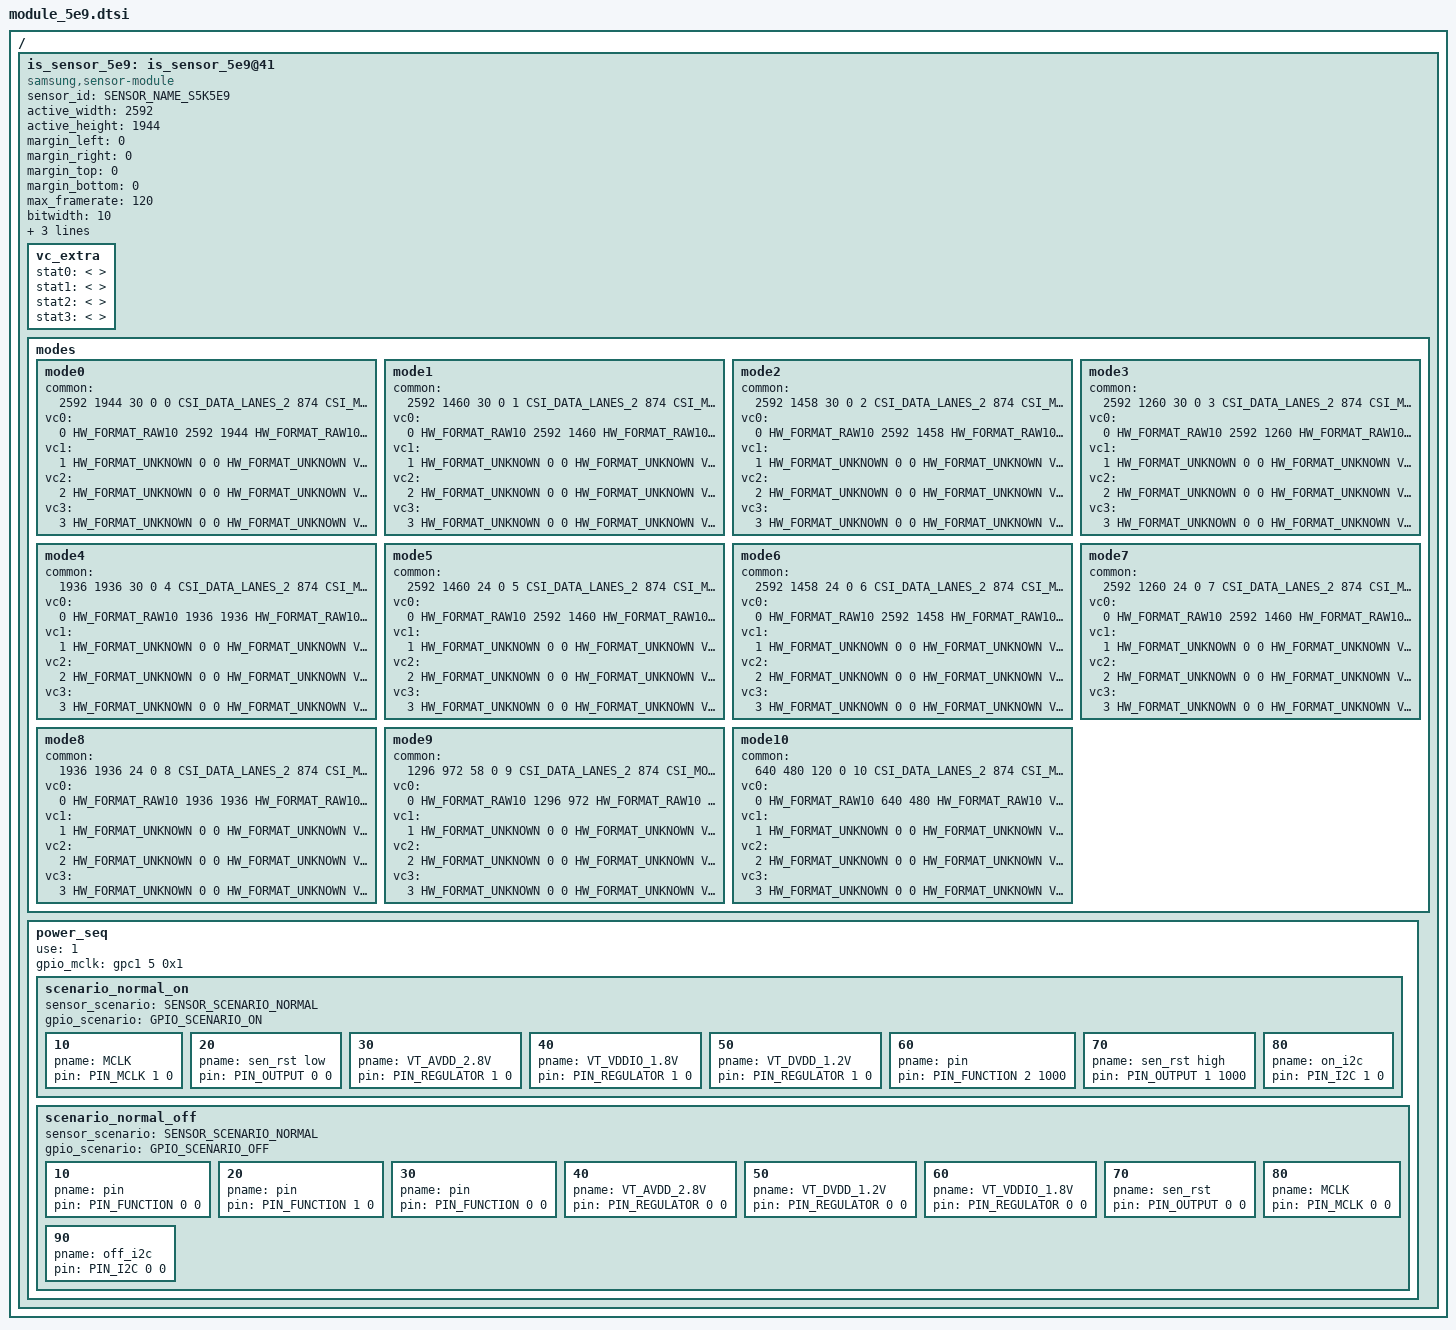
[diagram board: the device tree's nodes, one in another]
/*
 * SAMSUNG EXYNOSxxxx board camera device tree source
 *
 * Copyright (c) 2019 Samsung Electronics Co., Ltd.
 *		http://www.samsung.com
 *
 * This program is free software; you can redistribute it and/or modify
 * it under the terms of the GNU General Public License version 2 as
 * published by the Free Software Foundation.
 */

#include <dt-bindings/camera/exynos_is_dt.h>

/ {
	fragment@camera {
		target-path = "/";
		__overlay__ {
			is_sensor_5e9: is_sensor_5e9@41 {
				compatible = "samsung,sensor-module";

				/* common */
				sensor_id = <SENSOR_NAME_S5K5E9>;
				active_width = <2592>;
				active_height = <1944>;
				margin_left = <0>;
				margin_right = <0>;
				margin_top = <0>;
				margin_bottom = <0>;
				max_framerate = <120>;
				bitwidth = <10>;
				sensor_maker = "SLSI";
				sensor_name = "S5K5E9";
				setfile_name = "setfile_5e9.bin";

				status = "okay";

				vc_extra {
					/* ex) statX = <stat_type, sensor_mode, max_width, max_height, max_element> */
					stat0 = </* not avaliable */>;	/* VC_BUF_DATA_TYPE_SENSOR_STAT1 */
					stat1 = </* not avaliable */>;	/* VC_BUF_DATA_TYPE_GENERAL_STAT1 */
					stat2 = </* not avaliable */>;	/* VC_BUF_DATA_TYPE_SENSOR_STAT2 */
					stat3 = </* not avaliable */>;	/* VC_BUF_DATA_TYPE_GENERAL_STAT2 */
				};

				/* sensor modes */
				modes {
						/* common = <width, height, fps, settle, mode, lane, speed, interleave, lrte, pd_mode> */
						/* vcX = <map, hwformat, width, height, hwformat, type, width, height> */
					mode0 {
						common = <2592 1944 30 0 0 CSI_DATA_LANES_2 874 CSI_MODE_VC_ONLY LRTE_DISABLE PD_NONE EX_NONE>;
						vc0 = </* in */ 0 HW_FORMAT_RAW10 2592 1944	/* out */ HW_FORMAT_RAW10 VC_NOTHING 2592 1944>;
						vc1 = </* in */ 1 HW_FORMAT_UNKNOWN 0 0		/* out */ HW_FORMAT_UNKNOWN VC_NOTHING 0 0>;
						vc2 = </* in */ 2 HW_FORMAT_UNKNOWN 0 0		/* out */ HW_FORMAT_UNKNOWN VC_NOTHING 0 0>;
						vc3 = </* in */ 3 HW_FORMAT_UNKNOWN 0 0		/* out */ HW_FORMAT_UNKNOWN VC_NOTHING 0 0>;
					};
					mode1 {
						common = <2592 1460 30 0 1 CSI_DATA_LANES_2 874 CSI_MODE_VC_ONLY LRTE_DISABLE PD_NONE EX_NONE>;
						vc0 = <0 HW_FORMAT_RAW10 2592 1460	/* out */ HW_FORMAT_RAW10 VC_NOTHING 0 0>;
						vc1 = <1 HW_FORMAT_UNKNOWN 0 0		/* out */ HW_FORMAT_UNKNOWN VC_NOTHING 0 0>;
						vc2 = <2 HW_FORMAT_UNKNOWN 0 0		/* out */ HW_FORMAT_UNKNOWN VC_NOTHING 0 0>;
						vc3 = <3 HW_FORMAT_UNKNOWN 0 0		/* out */ HW_FORMAT_UNKNOWN VC_NOTHING 0 0>;
					};
					mode2 {
						common = <2592 1458 30 0 2 CSI_DATA_LANES_2 874 CSI_MODE_VC_ONLY LRTE_DISABLE PD_NONE EX_NONE>;
						vc0 = <0 HW_FORMAT_RAW10 2592 1458	/* out */ HW_FORMAT_RAW10 VC_NOTHING 0 0>;
						vc1 = <1 HW_FORMAT_UNKNOWN 0 0		/* out */ HW_FORMAT_UNKNOWN VC_NOTHING 0 0>;
						vc2 = <2 HW_FORMAT_UNKNOWN 0 0		/* out */ HW_FORMAT_UNKNOWN VC_NOTHING 0 0>;
						vc3 = <3 HW_FORMAT_UNKNOWN 0 0		/* out */ HW_FORMAT_UNKNOWN VC_NOTHING 0 0>;
					};
					mode3 {
						common = <2592 1260 30 0 3 CSI_DATA_LANES_2 874 CSI_MODE_VC_ONLY LRTE_DISABLE PD_NONE EX_NONE>;
						vc0 = <0 HW_FORMAT_RAW10 2592 1260	/* out */ HW_FORMAT_RAW10 VC_NOTHING 0 0>;
						vc1 = <1 HW_FORMAT_UNKNOWN 0 0		/* out */ HW_FORMAT_UNKNOWN VC_NOTHING 0 0>;
						vc2 = <2 HW_FORMAT_UNKNOWN 0 0		/* out */ HW_FORMAT_UNKNOWN VC_NOTHING 0 0>;
						vc3 = <3 HW_FORMAT_UNKNOWN 0 0		/* out */ HW_FORMAT_UNKNOWN VC_NOTHING 0 0>;
					};
					mode4 {
						common = <1936 1936 30 0 4 CSI_DATA_LANES_2 874 CSI_MODE_VC_ONLY LRTE_DISABLE PD_NONE EX_NONE>;
						vc0 = <0 HW_FORMAT_RAW10 1936 1936	/* out */ HW_FORMAT_RAW10 VC_NOTHING 0 0>;
						vc1 = <1 HW_FORMAT_UNKNOWN 0 0		/* out */ HW_FORMAT_UNKNOWN VC_NOTHING 0 0>;
						vc2 = <2 HW_FORMAT_UNKNOWN 0 0		/* out */ HW_FORMAT_UNKNOWN VC_NOTHING 0 0>;
						vc3 = <3 HW_FORMAT_UNKNOWN 0 0		/* out */ HW_FORMAT_UNKNOWN VC_NOTHING 0 0>;
					};
					mode5 {
						common = <2592 1460 24 0 5 CSI_DATA_LANES_2 874 CSI_MODE_VC_ONLY LRTE_DISABLE PD_NONE EX_NONE>;
						vc0 = <0 HW_FORMAT_RAW10 2592 1460	/* out */ HW_FORMAT_RAW10 VC_NOTHING 0 0>;
						vc1 = <1 HW_FORMAT_UNKNOWN 0 0		/* out */ HW_FORMAT_UNKNOWN VC_NOTHING 0 0>;
						vc2 = <2 HW_FORMAT_UNKNOWN 0 0		/* out */ HW_FORMAT_UNKNOWN VC_NOTHING 0 0>;
						vc3 = <3 HW_FORMAT_UNKNOWN 0 0		/* out */ HW_FORMAT_UNKNOWN VC_NOTHING 0 0>;
					};
					mode6 {
						common = <2592 1458 24 0 6 CSI_DATA_LANES_2 874 CSI_MODE_VC_ONLY LRTE_DISABLE PD_NONE EX_NONE>;
						vc0 = <0 HW_FORMAT_RAW10 2592 1458	/* out */ HW_FORMAT_RAW10 VC_NOTHING 0 0>;
						vc1 = <1 HW_FORMAT_UNKNOWN 0 0		/* out */ HW_FORMAT_UNKNOWN VC_NOTHING 0 0>;
						vc2 = <2 HW_FORMAT_UNKNOWN 0 0		/* out */ HW_FORMAT_UNKNOWN VC_NOTHING 0 0>;
						vc3 = <3 HW_FORMAT_UNKNOWN 0 0		/* out */ HW_FORMAT_UNKNOWN VC_NOTHING 0 0>;
					};
					mode7 {
						common = <2592 1260 24 0 7 CSI_DATA_LANES_2 874 CSI_MODE_VC_ONLY LRTE_DISABLE PD_NONE EX_NONE>;
						vc0 = <0 HW_FORMAT_RAW10 2592 1460	/* out */ HW_FORMAT_RAW10 VC_NOTHING 0 0>;
						vc1 = <1 HW_FORMAT_UNKNOWN 0 0		/* out */ HW_FORMAT_UNKNOWN VC_NOTHING 0 0>;
						vc2 = <2 HW_FORMAT_UNKNOWN 0 0		/* out */ HW_FORMAT_UNKNOWN VC_NOTHING 0 0>;
						vc3 = <3 HW_FORMAT_UNKNOWN 0 0		/* out */ HW_FORMAT_UNKNOWN VC_NOTHING 0 0>;
					};
					mode8 {
						common = <1936 1936 24 0 8 CSI_DATA_LANES_2 874 CSI_MODE_VC_ONLY LRTE_DISABLE PD_NONE EX_NONE>;
						vc0 = <0 HW_FORMAT_RAW10 1936 1936	/* out */ HW_FORMAT_RAW10 VC_NOTHING 0 0>;
						vc1 = <1 HW_FORMAT_UNKNOWN 0 0		/* out */ HW_FORMAT_UNKNOWN VC_NOTHING 0 0>;
						vc2 = <2 HW_FORMAT_UNKNOWN 0 0		/* out */ HW_FORMAT_UNKNOWN VC_NOTHING 0 0>;
						vc3 = <3 HW_FORMAT_UNKNOWN 0 0		/* out */ HW_FORMAT_UNKNOWN VC_NOTHING 0 0>;
					};
					mode9 {
						common = <1296 972 58 0 9 CSI_DATA_LANES_2 874 CSI_MODE_VC_ONLY LRTE_DISABLE PD_NONE EX_NONE>;
						vc0 = <0 HW_FORMAT_RAW10 1296 972	/* out */ HW_FORMAT_RAW10 VC_NOTHING 0 0>;
						vc1 = <1 HW_FORMAT_UNKNOWN 0 0		/* out */ HW_FORMAT_UNKNOWN VC_NOTHING 0 0>;
						vc2 = <2 HW_FORMAT_UNKNOWN 0 0		/* out */ HW_FORMAT_UNKNOWN VC_NOTHING 0 0>;
						vc3 = <3 HW_FORMAT_UNKNOWN 0 0		/* out */ HW_FORMAT_UNKNOWN VC_NOTHING 0 0>;
					};
					mode10 {
						common = <640 480 120 0 10 CSI_DATA_LANES_2 874 CSI_MODE_VC_ONLY LRTE_DISABLE PD_NONE EX_NONE>;
						vc0 = <0 HW_FORMAT_RAW10 640 480	/* out */ HW_FORMAT_RAW10 VC_NOTHING 0 0>;
						vc1 = <1 HW_FORMAT_UNKNOWN 0 0		/* out */ HW_FORMAT_UNKNOWN VC_NOTHING 0 0>;
						vc2 = <2 HW_FORMAT_UNKNOWN 0 0		/* out */ HW_FORMAT_UNKNOWN VC_NOTHING 0 0>;
						vc3 = <3 HW_FORMAT_UNKNOWN 0 0		/* out */ HW_FORMAT_UNKNOWN VC_NOTHING 0 0>;
					};
				};

				power_seq {
					use = <1>;
					gpio_mclk = <&gpc1 5 0x1>;

					scenario_normal_on {
						sensor_scenario = <SENSOR_SCENARIO_NORMAL>;
						gpio_scenario = <GPIO_SCENARIO_ON>;

						/* A start node number should be over the 10 for reserved number 0~9. */
						/* pname = "name"; pin = <act value dealy voltage>; gpio = <gpx# # 0x1>; */
						10 { pname = "MCLK"; pin = <PIN_MCLK 1 0>; };
						20 { pname = "sen_rst low"; pin = <PIN_OUTPUT 0 0>; };
						30 { pname = "VT_AVDD_2.8V"; pin = <PIN_REGULATOR 1 0>; };
						40 { pname = "VT_VDDIO_1.8V"; pin = <PIN_REGULATOR 1 0>; };
						50 { pname = "VT_DVDD_1.2V"; pin = <PIN_REGULATOR 1 0>; };
						60 { pname = "pin"; pin = <PIN_FUNCTION 2 1000>; };
						70 { pname = "sen_rst high"; pin = <PIN_OUTPUT 1 1000>; };
						80 { pname = "on_i2c"; pin = <PIN_I2C 1 0>; };
					};

					scenario_normal_off {
						sensor_scenario = <SENSOR_SCENARIO_NORMAL>;
						gpio_scenario = <GPIO_SCENARIO_OFF>;

						/* A start node number should be over the 10 for reserved number 0~9. */
						/* pname = "name"; pin = <act value dealy voltage>; gpio = <gpx# # 0x1>; */
						10 { pname = "pin"; pin = <PIN_FUNCTION 0 0>; };
						20 { pname = "pin"; pin = <PIN_FUNCTION 1 0>; };
						30 { pname = "pin"; pin = <PIN_FUNCTION 0 0>; };
						40 { pname = "VT_AVDD_2.8V"; pin = <PIN_REGULATOR 0 0>; };
						50 { pname = "VT_DVDD_1.2V"; pin = <PIN_REGULATOR 0 0>; };
						60 { pname = "VT_VDDIO_1.8V"; pin = <PIN_REGULATOR 0 0>; };
						70 { pname = "sen_rst"; pin = <PIN_OUTPUT 0 0>; };
						80 { pname = "MCLK"; pin = <PIN_MCLK 0 0>; };
						90 { pname = "off_i2c"; pin = <PIN_I2C 0 0>; };
					};
				};
			};
		}; /* end of __overlay__ */
	}; /* end of fragment */
}; /* end of root */
